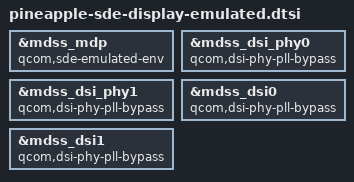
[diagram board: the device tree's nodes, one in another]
&mdss_mdp {
	qcom,sde-emulated-env;
};

&mdss_dsi_phy0 {
	qcom,dsi-phy-pll-bypass;
};

&mdss_dsi_phy1 {
	qcom,dsi-phy-pll-bypass;
};

&mdss_dsi0 {
	qcom,dsi-phy-pll-bypass;
};

&mdss_dsi1 {
	qcom,dsi-phy-pll-bypass;
};


